# RX64M_MMCIF_Pilot register map
File version: 1.0
RX64M_MMCIF_Pilot peripheral registers generated from iodefine.h (pilot).
Registers are 32-bit, read-write, reset 0x0 unless marked. A register's access mark holds for its fields unless they carry their own. Offsets are from the block's base; lines under a group give offsets from that group; [hi:lo] are bit positions; {n}, {i} and the like mark numbered series; 'fields as' and 'values as' point back to an identical list; <NAME> marks a mode.

## Memory map
0x00088500 MMCIF size 0x80

## MMCIF
Base 0x00088500
0x00 CECMDSET
0x08 CEARG
  [31:0] ARG
0x0C CEARGCMD12
  [31:0] C12ARG
0x10 CECMDCTRL
  [0] BREAK
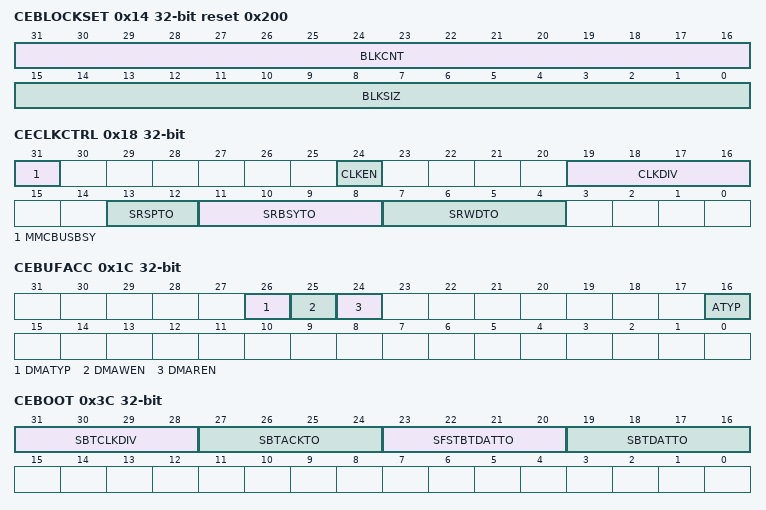
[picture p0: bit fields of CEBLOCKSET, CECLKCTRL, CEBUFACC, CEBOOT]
0x14 CEBLOCKSET reset 0x200
  [31:16] BLKCNT, [15:0] BLKSIZ
0x18 CECLKCTRL
  [31] MMCBUSBSY, [24] CLKEN, [19:16] CLKDIV, [13:12] SRSPTO, [11:8] SRBSYTO, [7:4] SRWDTO
0x1C CEBUFACC
  [26] DMATYP, [25] DMAWEN, [24] DMAREN, [16] ATYP
0x20 CERESP3 ro
0x24 CERESP2 ro
0x28 CERESP1 ro
0x2C CERESP0 ro
0x30 CERESPCMD12 ro
  [31:0] RSP12
0x34 CEDATA
0x3C CEBOOT
  [31:28] SBTCLKDIV, [27:24] SBTACKTO, [23:20] SFSTBTDATTO, [19:16] SBTDATTO
0x40 CEINT
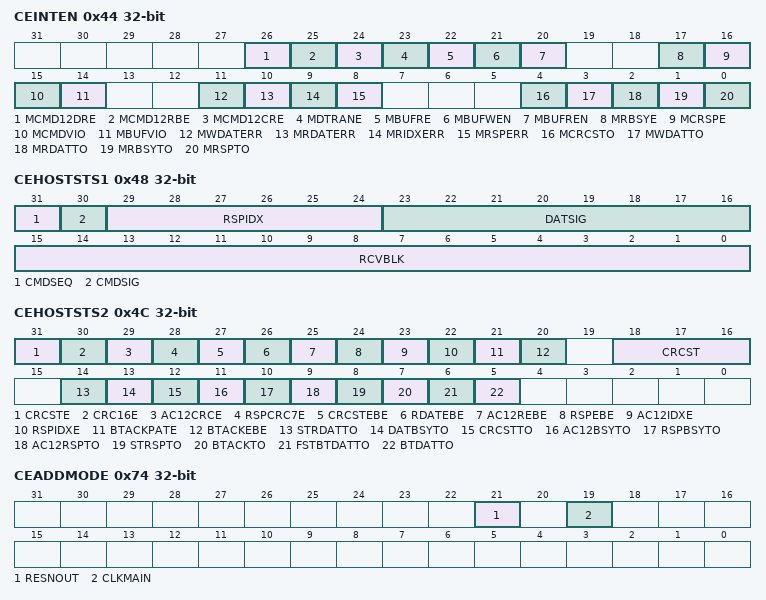
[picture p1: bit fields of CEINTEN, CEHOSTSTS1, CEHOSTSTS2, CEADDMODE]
0x44 CEINTEN
  [26] MCMD12DRE, [25] MCMD12RBE, [24] MCMD12CRE, [23] MDTRANE, [22] MBUFRE, [21] MBUFWEN, [20] MBUFREN, [17] MRBSYE, [16] MCRSPE, [15] MCMDVIO, [14] MBUFVIO, [11] MWDATERR, [10] MRDATERR, [9] MRIDXERR, [8] MRSPERR, [4] MCRCSTO, [3] MWDATTO, [2] MRDATTO, [1] MRBSYTO, [0] MRSPTO
0x48 CEHOSTSTS1 ro (reset mask 0xBF00FFFF)
  [31] CMDSEQ, [30] CMDSIG, [29:24] RSPIDX, [23:16] DATSIG, [15:0] RCVBLK
0x4C CEHOSTSTS2
  [31] CRCSTE, [30] CRC16E, [29] AC12CRCE, [28] RSPCRC7E, [27] CRCSTEBE, [26] RDATEBE, [25] AC12REBE, [24] RSPEBE, [23] AC12IDXE, [22] RSPIDXE, [21] BTACKPATE, [20] BTACKEBE, [18:16] CRCST, [14] STRDATTO, [13] DATBSYTO, [12] CRCSTTO, [11] AC12BSYTO, [10] RSPBSYTO, [9] AC12RSPTO, [8] STRSPTO, [7] BTACKTO, [6] FSTBTDATTO, [5] BTDATTO
0x70 CEDETECT (reset mask 0xFFFFBBFF)
0x74 CEADDMODE
  [21] RESNOUT, [19] CLKMAIN
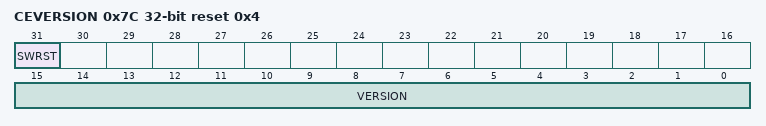
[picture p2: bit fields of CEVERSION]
0x7C CEVERSION reset 0x4
  [31] SWRST, [15:0] VERSION
